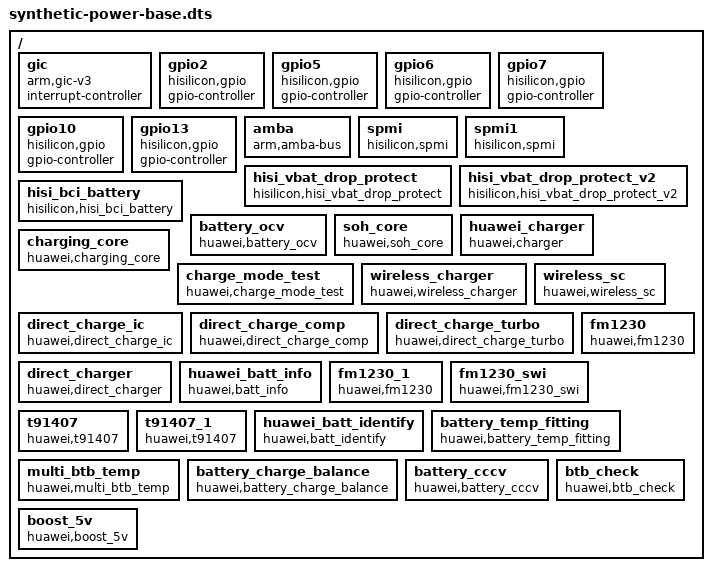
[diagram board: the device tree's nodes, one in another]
/dts-v1/;

/*
 * Synthetic base tree for `base-power-overlay.dts`.
 *
 * Exists so the seed overlay's `&label { ... }` fragments and phandle
 * references resolve during real `dtc`/`fdtoverlay` compilation. Compatible
 * strings use realistic vendor prefixes (hisilicon / huawei / arm) so the
 * workbench demo does not surface a synthetic `wiseeff,` vendor. GPIO
 * controllers declare `gpio-controller` and `#gpio-cells = <2>` so
 * `<&gpioN pin flags>` cells are well-formed.
 */

/ {
	#address-cells = <1>;
	#size-cells = <1>;

	gic: gic {
		compatible = "arm,gic-v3";
		interrupt-controller;
		#interrupt-cells = <3>;
	};

	gpio2: gpio2 {
		compatible = "hisilicon,gpio";
		gpio-controller;
		#gpio-cells = <2>;
	};

	gpio5: gpio5 {
		compatible = "hisilicon,gpio";
		gpio-controller;
		#gpio-cells = <2>;
	};

	gpio6: gpio6 {
		compatible = "hisilicon,gpio";
		gpio-controller;
		#gpio-cells = <2>;
	};

	gpio7: gpio7 {
		compatible = "hisilicon,gpio";
		gpio-controller;
		#gpio-cells = <2>;
	};

	gpio10: gpio10 {
		compatible = "hisilicon,gpio";
		gpio-controller;
		#gpio-cells = <2>;
	};

	gpio13: gpio13 {
		compatible = "hisilicon,gpio";
		gpio-controller;
		#gpio-cells = <2>;
	};

	amba: amba {
		compatible = "arm,amba-bus";
	};

	spmi: spmi {
		compatible = "hisilicon,spmi";
	};

	spmi1: spmi1 {
		compatible = "hisilicon,spmi";
	};

	hisi_vbat_drop_protect: hisi_vbat_drop_protect {
		compatible = "hisilicon,hisi_vbat_drop_protect";
	};

	hisi_vbat_drop_protect_v2: hisi_vbat_drop_protect_v2 {
		compatible = "hisilicon,hisi_vbat_drop_protect_v2";
	};

	hisi_bci_battery: hisi_bci_battery {
		compatible = "hisilicon,hisi_bci_battery";
	};

	battery_ocv: battery_ocv {
		compatible = "huawei,battery_ocv";
	};

	soh_core: soh_core {
		compatible = "huawei,soh_core";
	};

	huawei_charger: huawei_charger {
		compatible = "huawei,charger";
	};

	charging_core: charging_core {
		compatible = "huawei,charging_core";
	};

	charge_mode_test: charge_mode_test {
		compatible = "huawei,charge_mode_test";
	};

	wireless_charger: wireless_charger {
		compatible = "huawei,wireless_charger";
	};

	wireless_sc: wireless_sc {
		compatible = "huawei,wireless_sc";
	};

	direct_charge_ic: direct_charge_ic {
		compatible = "huawei,direct_charge_ic";
	};

	direct_charge_comp: direct_charge_comp {
		compatible = "huawei,direct_charge_comp";
	};

	direct_charge_turbo: direct_charge_turbo {
		compatible = "huawei,direct_charge_turbo";
	};

	direct_charger: direct_charger {
		compatible = "huawei,direct_charger";
	};

	huawei_batt_info: huawei_batt_info {
		compatible = "huawei,batt_info";
	};

	fm1230: fm1230 {
		compatible = "huawei,fm1230";
	};

	fm1230_1: fm1230_1 {
		compatible = "huawei,fm1230";
	};

	fm1230_swi: fm1230_swi {
		compatible = "huawei,fm1230_swi";
	};

	t91407: t91407 {
		compatible = "huawei,t91407";
	};

	t91407_1: t91407_1 {
		compatible = "huawei,t91407";
	};

	huawei_batt_identify: huawei_batt_identify {
		compatible = "huawei,batt_identify";
	};

	battery_temp_fitting: battery_temp_fitting {
		compatible = "huawei,battery_temp_fitting";
	};

	multi_btb_temp: multi_btb_temp {
		compatible = "huawei,multi_btb_temp";
	};

	battery_charge_balance: battery_charge_balance {
		compatible = "huawei,battery_charge_balance";
	};

	battery_cccv: battery_cccv {
		compatible = "huawei,battery_cccv";
	};

	btb_check: btb_check {
		compatible = "huawei,btb_check";
	};

	boost_5v: boost_5v {
		compatible = "huawei,boost_5v";
	};
};
